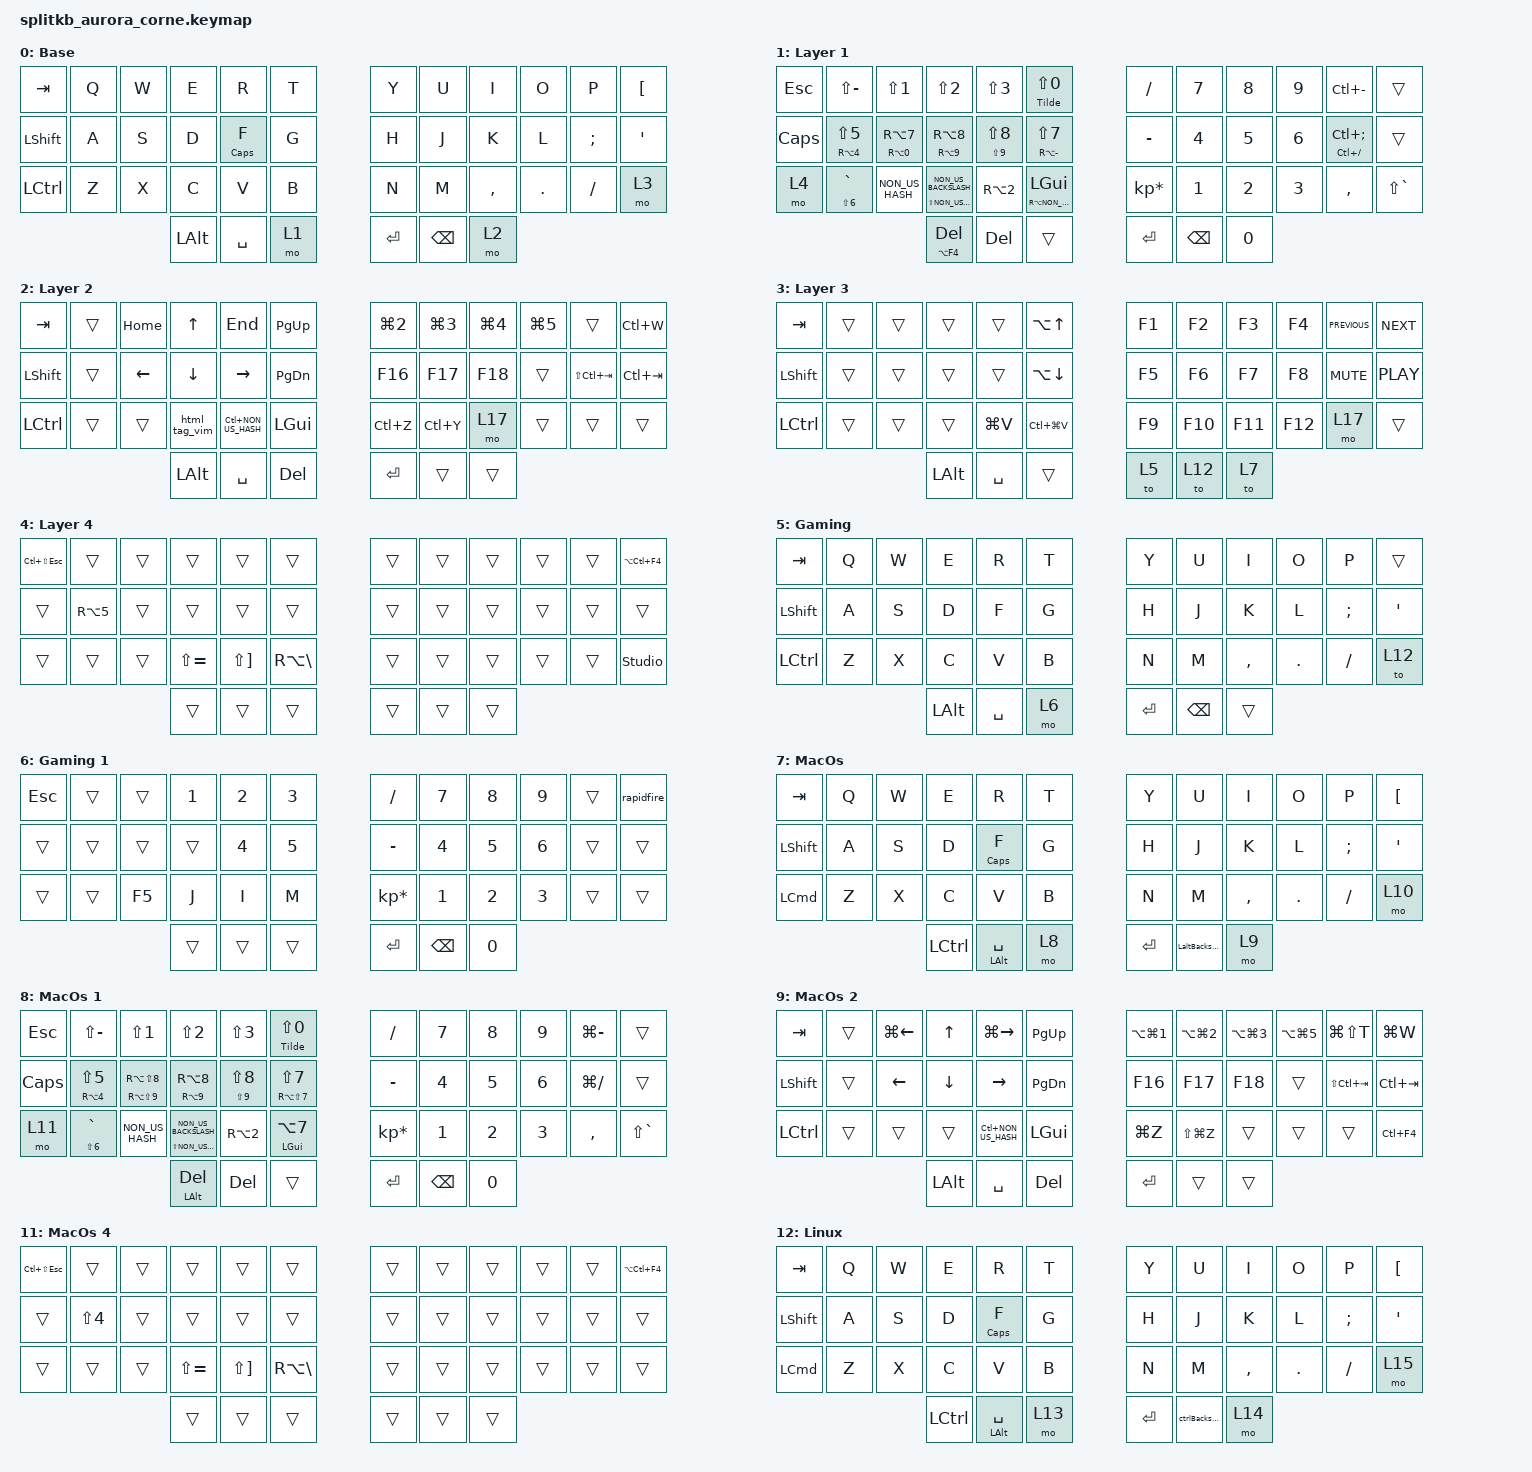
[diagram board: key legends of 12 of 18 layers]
/*
 * Copyright (c) 2020 The ZMK Contributors
 *
 * SPDX-License-Identifier: MIT
 */

#include <behaviors.dtsi>
#include <dt-bindings/zmk/bt.h>
#include <dt-bindings/zmk/keys.h>

/ {
    macros {
        Tilde: Tilde {
            compatible = "zmk,behavior-macro";
            #binding-cells = <0>;
            bindings = <&kp RA(RIGHT_BRACKET) &kp SPACE>;
            label = "TILDE";
        };

        html_tag_vim: html_tag_vim {
            compatible = "zmk,behavior-macro";
            #binding-cells = <0>;
            bindings = <&kp Y &kp S &kp L &kp NON_US_BACKSLASH>;
            label = "HTML_TAG_VIM";
        };

        rampytys: rampytys {
            compatible = "zmk,behavior-macro";
            #binding-cells = <0>;
            bindings = <&kp SPACE &kp SPACE &kp SPACE &kp SPACE &kp SPACE &kp SPACE &kp SPACE &kp SPACE &kp SPACE &kp SPACE &kp SPACE &kp SPACE &kp SPACE &kp SPACE &kp SPACE &kp SPACE &kp SPACE &kp SPACE &kp SPACE &kp SPACE &kp SPACE &kp SPACE &kp SPACE &kp SPACE &kp SPACE &kp SPACE &kp SPACE &kp SPACE &kp SPACE &kp SPACE &kp SPACE &kp SPACE &kp SPACE &kp SPACE &kp SPACE &kp SPACE &kp SPACE &kp SPACE &kp SPACE &kp SPACE &kp SPACE &kp SPACE &kp SPACE &kp SPACE &kp SPACE &kp SPACE &kp SPACE &kp SPACE &kp SPACE &kp SPACE &kp SPACE &kp SPACE &kp SPACE &kp SPACE &kp SPACE &kp SPACE &kp SPACE &kp SPACE &kp SPACE &kp SPACE &kp SPACE &kp SPACE &kp SPACE &kp SPACE &kp SPACE &kp SPACE &kp SPACE &kp SPACE &kp SPACE &kp SPACE &kp SPACE &kp SPACE &kp SPACE &kp SPACE &kp SPACE &kp SPACE &kp SPACE &kp SPACE &kp SPACE &kp SPACE &kp SPACE &kp SPACE &kp SPACE &kp SPACE &kp SPACE &kp SPACE &kp SPACE &kp SPACE &kp SPACE &kp SPACE &kp SPACE &kp SPACE &kp SPACE &kp SPACE &kp SPACE &kp SPACE &kp SPACE &kp SPACE &kp SPACE &kp SPACE &kp SPACE &kp SPACE &kp SPACE &kp SPACE &kp SPACE &kp SPACE &kp SPACE &kp SPACE &kp SPACE &kp SPACE &kp SPACE &kp SPACE &kp SPACE &kp SPACE &kp SPACE &kp SPACE &kp SPACE &kp SPACE &kp SPACE &kp SPACE &kp SPACE &kp SPACE &kp SPACE &kp SPACE &kp SPACE &kp SPACE &kp SPACE &kp SPACE &kp SPACE &kp SPACE &kp SPACE &kp SPACE &kp SPACE &kp SPACE &kp SPACE &kp SPACE &kp SPACE &kp SPACE &kp SPACE &kp SPACE &kp SPACE &kp SPACE &kp SPACE &kp SPACE &kp SPACE &kp SPACE &kp SPACE &kp SPACE &kp SPACE &kp SPACE &kp SPACE &kp SPACE &kp SPACE &kp SPACE &kp SPACE &kp SPACE &kp SPACE &kp SPACE &kp SPACE &kp SPACE &kp SPACE &kp SPACE>;
            label = "RAMPYTYS";
            wait-ms = <150>;
        };
    };

    behaviors {
        rapidfire: rapidfire {
            compatible = "zmk,behavior-rapidfire";
            #binding-cells = <0>;
            label = "RAPIDFIRE";
            keycode = <E>;
            tap-ms = <6>;
            wait-ms = <3>;
        };

        equals_tilde: equals_tilde {
            compatible = "zmk,behavior-hold-tap";
            label = "EQUALS_TILDE";
            bindings = <&Tilde>, <&kp>;

            #binding-cells = <2>;
            tapping-term-ms = <150>;
        };

        Custom_Hold_Tap: Custom_Hold_Tap {
            compatible = "zmk,behavior-hold-tap";
            label = "CUSTOM_HOLD_TAP";
            bindings = <&kp>, <&kp>;

            #binding-cells = <2>;
            tapping-term-ms = <200>;
            flavor = "tap-preferred";
        };

        LaltBackspace: LaltBackspace {
            compatible = "zmk,behavior-mod-morph";
            label = "LALTBACKSPACE";
            bindings = <&kp BACKSPACE>, <&kp LA(BACKSPACE)>;

            #binding-cells = <0>;
            mods = <(MOD_LGUI)>;
        };

        ctrlBackspace: ctrlBackspace {
            compatible = "zmk,behavior-mod-morph";
            label = "CTRLBACKSPACE";
            bindings = <&kp BACKSPACE>, <&kp LC(BACKSPACE)>;

            #binding-cells = <0>;
            mods = <(MOD_LGUI)>;
        };
    };

    combos { compatible = "zmk,combos"; };

    keymap {
        compatible = "zmk,keymap";

        default_layer {
            display-name = "Base";

            // -----------------------------------------------------------------------------------------
            // |  TAB |  Q  |  W  |  E  |  R  |  T  |   |  Y  |  U   |  I  |  O  |  P  | BKSP |
            // | CTRL |  A  |  S  |  D  |  F  |  G  |   |  H  |  J   |  K  |  L  |  ;  |  '   |
            // | SHFT |  Z  |  X  |  C  |  V  |  B  |   |  N  |  M   |  ,  |  .  |  /  | ESC  |
            //                    | GUI | LWR | SPC |   | ENT | RSE  | ALT |

            bindings = <
&kp TAB         &kp Q  &kp W  &kp E         &kp R                    &kp T    &kp Y    &kp U          &kp I      &kp O    &kp P     &kp LEFT_BRACKET
&kp LEFT_SHIFT  &kp A  &kp S  &kp D         &Custom_Hold_Tap CAPS F  &kp G    &kp H    &kp J          &kp K      &kp L    &kp SEMI  &kp SINGLE_QUOTE
&kp LCTRL       &kp Z  &kp X  &kp C         &kp V                    &kp B    &kp N    &kp M          &kp COMMA  &kp DOT  &kp FSLH  &mo 3
                              &kp LEFT_ALT  &kp SPACE                &mo 1    &kp RET  &kp BACKSPACE  &mo 2
            >;
        };

        lower_layer {
            display-name = "Layer 1";

            // -----------------------------------------------------------------------------------------
            // |  TAB |  1  |  2  |  3  |  4  |  5  |   |  6  |  7  |  8  |  9  |  0  | BKSP |
            // | BTCLR| BT1 | BT2 | BT3 | BT4 | BT5 |   | LFT | DWN |  UP | RGT |     |      |
            // | SHFT |     |     |     |     |     |   |     |     |     |     |     |      |
            //                    | GUI |     | SPC |   | ENT |     | ALT |

            bindings = <
&kp ESCAPE  &kp LS(MINUS)                  &kp LS(NUMBER_1)               &kp LS(NUMBER_2)                           &kp LS(NUMBER_3)               &equals_tilde 0 LS(NUMBER_0)     &kp SLASH        &kp NUMBER_7   &kp N8        &kp N9        &kp LC(MINUS)                &trans
&kp CAPS    &mt RA(NUMBER_4) LS(NUMBER_5)  &mt RA(NUMBER_0) RA(NUMBER_7)  &mt RA(NUMBER_9) RA(NUMBER_8)              &mt LS(NUMBER_9) LS(NUMBER_8)  &mt RA(MINUS) LS(NUMBER_7)       &kp MINUS        &kp NUMBER_4   &kp NUMBER_5  &kp NUMBER_6  &mt LC(SLASH) LC(SEMICOLON)  &trans
&mo 4       &mt LS(NUMBER_6) GRAVE         &kp NON_US_HASH                &mt LS(NON_US_BACKSLASH) NON_US_BACKSLASH  &kp RA(NUMBER_2)               &mt RA(NON_US_BACKSLASH) LGUI    &kp KP_ASTERISK  &kp NUMBER_1   &kp NUMBER_2  &kp NUMBER_3  &kp COMMA                    &kp LS(GRAVE)
                                                                          &mt LA(F4) DELETE                          &kp DELETE                     &trans                           &kp RET          &kp BACKSPACE  &kp NUMBER_0
            >;
        };

        raise_layer {
            display-name = "Layer 2";

            // -----------------------------------------------------------------------------------------
            // |  TAB |  !  |  @  |  #  |  $  |  %  |   |  ^  |  &  |  *  |  (  |  )  | BKSP |
            // | CTRL |     |     |     |     |     |   |  -  |  =  |  [  |  ]  |  \  |  `   |
            // | SHFT |     |     |     |     |     |   |  _  |  +  |  {  |  }  | "|" |  ~   |
            //                    | GUI |     | SPC |   | ENT |     | ALT |

            bindings = <
&kp TAB         &trans  &kp HOME  &kp UP         &kp END              &kp PAGE_UP      &kp LG(NUMBER_2)  &kp LG(NUMBER_3)  &kp LG(NUMBER_4)  &kp LG(NUMBER_5)  &trans           &kp LC(W)
&kp LEFT_SHIFT  &trans  &kp LEFT  &kp DOWN       &kp RIGHT            &kp PAGE_DOWN    &kp F16           &kp F17           &kp F18           &trans            &kp LS(LC(TAB))  &kp LC(TAB)
&kp LCTRL       &trans  &trans    &html_tag_vim  &kp LC(NON_US_HASH)  &kp LGUI         &kp LC(Z)         &kp LC(Y)         &mo 17            &trans            &trans           &trans
                                  &kp LEFT_ALT   &kp SPACE            &kp DEL          &kp RET           &trans            &trans
            >;
        };

        layer_3 {
            display-name = "Layer 3";
            bindings = <
&kp TAB         &trans  &trans  &trans        &trans     &kp LA(UP_ARROW)    &kp F1  &kp F2   &kp F3   &kp F4   &kp C_PREVIOUS  &kp C_NEXT
&kp LEFT_SHIFT  &trans  &trans  &trans        &trans     &kp LA(DOWN)        &kp F5  &kp F6   &kp F7   &kp F8   &kp C_MUTE      &kp C_PLAY
&kp LCTRL       &trans  &trans  &trans        &kp LG(V)  &kp LC(LG(V))       &kp F9  &kp F10  &kp F11  &kp F12  &mo 17          &trans
                                &kp LEFT_ALT  &kp SPACE  &trans              &to 5   &to 12   &to 7
            >;
        };

        layer_4 {
            display-name = "Layer 4";
            bindings = <
&kp LC(LS(ESCAPE))  &trans            &trans  &trans         &trans                 &trans               &trans  &trans  &trans  &trans  &trans  &kp LA(LC(F4))
&trans              &kp RA(NUMBER_5)  &trans  &trans         &trans                 &trans               &trans  &trans  &trans  &trans  &trans  &trans
&trans              &trans            &trans  &kp LS(EQUAL)  &kp LS(RIGHT_BRACKET)  &kp RA(BACKSLASH)    &trans  &trans  &trans  &trans  &trans  &studio_unlock
                                              &trans         &trans                 &trans               &trans  &trans  &trans
            >;
        };

        Gaming {
            display-name = "Gaming";
            bindings = <
&kp TAB           &kp Q  &kp W  &kp E         &kp R      &kp T    &kp Y      &kp U          &kp I      &kp O       &kp P          &trans
&kp LEFT_SHIFT    &kp A  &kp S  &kp D         &kp F      &kp G    &kp H      &kp J          &kp K      &kp L       &kp SEMICOLON  &kp SINGLE_QUOTE
&kp LEFT_CONTROL  &kp Z  &kp X  &kp C         &kp V      &kp B    &kp N      &kp M          &kp COMMA  &kp PERIOD  &kp SLASH      &to 12
                                &kp LEFT_ALT  &kp SPACE  &mo 6    &kp ENTER  &kp BACKSPACE  &trans
            >;
        };

        Gaming_1 {
            display-name = "Gaming 1";
            bindings = <
&kp ESCAPE  &trans  &trans  &kp NUMBER_1  &kp NUMBER_2  &kp NUMBER_3    &kp SLASH        &kp N7         &kp N8        &kp N9        &trans  &rapidfire
&trans      &trans  &trans  &trans        &kp NUMBER_4  &kp NUMBER_5    &kp MINUS        &kp NUMBER_4   &kp N5        &kp NUMBER_6  &trans  &trans
&trans      &trans  &kp F5  &kp J         &kp I         &kp M           &kp KP_MULTIPLY  &kp NUMBER_1   &kp NUMBER_2  &kp NUMBER_3  &trans  &trans
                            &trans        &trans        &trans          &kp ENTER        &kp BACKSPACE  &kp N0
            >;
        };

        MacOs {
            display-name = "MacOs";
            bindings = <
&kp TAB           &kp Q  &kp W  &kp E             &kp R                            &kp T    &kp Y    &kp U           &kp I      &kp O    &kp P     &kp LEFT_BRACKET
&kp LEFT_SHIFT    &kp A  &kp S  &kp D             &Custom_Hold_Tap CAPS F          &kp G    &kp H    &kp J           &kp K      &kp L    &kp SEMI  &kp SINGLE_QUOTE
&kp LEFT_COMMAND  &kp Z  &kp X  &kp C             &kp V                            &kp B    &kp N    &kp M           &kp COMMA  &kp DOT  &kp FSLH  &mo 10
                                &kp LEFT_CONTROL  &Custom_Hold_Tap LEFT_ALT SPACE  &mo 8    &kp RET  &LaltBackspace  &mo 9
            >;
        };

        MacOs_1 {
            display-name = "MacOs 1";
            bindings = <
&kp ESCAPE  &kp LS(MINUS)                  &kp LS(NUMBER_1)           &kp LS(NUMBER_2)                           &kp LS(NUMBER_3)               &equals_tilde 0 LS(NUMBER_0)    &kp SLASH        &kp NUMBER_7   &kp N8        &kp N9        &kp LG(MINUS)  &trans
&kp CAPS    &mt RA(NUMBER_4) LS(NUMBER_5)  &mt RA(LS(N9)) RA(LS(N8))  &mt RA(NUMBER_9) RA(NUMBER_8)              &mt LS(NUMBER_9) LS(NUMBER_8)  &mt RA(LS(N7)) LS(NUMBER_7)     &kp MINUS        &kp NUMBER_4   &kp NUMBER_5  &kp NUMBER_6  &kp LG(SLASH)  &trans
&mo 11      &mt LS(NUMBER_6) GRAVE         &kp NON_US_HASH            &mt LS(NON_US_BACKSLASH) NON_US_BACKSLASH  &kp RA(NUMBER_2)               &mt LGUI LA(N7)                 &kp KP_ASTERISK  &kp NUMBER_1   &kp NUMBER_2  &kp NUMBER_3  &kp COMMA      &kp LS(GRAVE)
                                                                      &mt LEFT_ALT DELETE                        &kp DELETE                     &trans                          &kp RET          &kp BACKSPACE  &kp NUMBER_0
            >;
        };

        MacOs_2 {
            display-name = "MacOs 2";
            bindings = <
&kp TAB         &trans  &kp LG(LEFT)  &kp UP        &kp LG(RIGHT_ARROW)  &kp PAGE_UP      &kp LA(LG(NUMBER_1))  &kp LA(LG(NUMBER_2))  &kp LA(LG(NUMBER_3))  &kp LA(LG(N5))  &kp LG(LS(T))    &kp LG(W)
&kp LEFT_SHIFT  &trans  &kp LEFT      &kp DOWN      &kp RIGHT            &kp PAGE_DOWN    &kp F16               &kp F17               &kp F18               &trans          &kp LS(LC(TAB))  &kp LC(TAB)
&kp LCTRL       &trans  &trans        &trans        &kp LC(NON_US_HASH)  &kp LGUI         &kp LG(Z)             &kp LS(LG(Z))         &trans                &trans          &trans           &kp LC(F4)
                                      &kp LEFT_ALT  &kp SPACE            &kp DEL          &kp RET               &trans                &trans
            >;
        };

        MacOs_3 {
            display-name = "MacOs 3";
            bindings = <
&kp TAB         &trans  &trans              &kp LC(UP_ARROW)  &trans                    &kp LA(UP_ARROW)      &kp F1  &kp F2   &kp F3   &kp F4   &kp C_PREVIOUS  &kp C_NEXT
&kp LEFT_SHIFT  &trans  &kp LC(LEFT_ARROW)  &kp LC(DOWN)      &kp LC(RIGHT_ARROW)       &kp LA(DOWN_ARROW)    &kp F5  &kp F6   &kp F7   &kp F8   &kp C_MUTE      &kp C_PLAY
&kp LCTRL       &trans  &trans              &kp LS(LG(N5))    &kp LS(LG(LC(NUMBER_4)))  &kp LG(LS(LA(V)))     &kp F9  &kp F10  &kp F11  &kp F12  &mo 17          &trans
                                            &kp LEFT_ALT      &kp SPACE                 &trans                &to 5   &to 12   &to 0
            >;
        };

        MacOs_4 {
            display-name = "MacOs 4";
            bindings = <
&kp LC(LS(ESCAPE))  &trans            &trans  &trans         &trans                 &trans               &trans  &trans  &trans  &trans  &trans  &kp LA(LC(F4))
&trans              &kp LS(NUMBER_4)  &trans  &trans         &trans                 &trans               &trans  &trans  &trans  &trans  &trans  &trans
&trans              &trans            &trans  &kp LS(EQUAL)  &kp LS(RIGHT_BRACKET)  &kp RA(BACKSLASH)    &trans  &trans  &trans  &trans  &trans  &trans
                                              &trans         &trans                 &trans               &trans  &trans  &trans
            >;
        };

        Linux {
            display-name = "Linux";
            bindings = <
&kp TAB           &kp Q  &kp W  &kp E             &kp R                            &kp T     &kp Y    &kp U           &kp I      &kp O    &kp P     &kp LEFT_BRACKET
&kp LEFT_SHIFT    &kp A  &kp S  &kp D             &Custom_Hold_Tap CAPS F          &kp G     &kp H    &kp J           &kp K      &kp L    &kp SEMI  &kp SINGLE_QUOTE
&kp LEFT_COMMAND  &kp Z  &kp X  &kp C             &kp V                            &kp B     &kp N    &kp M           &kp COMMA  &kp DOT  &kp FSLH  &mo 15
                                &kp LEFT_CONTROL  &Custom_Hold_Tap LEFT_ALT SPACE  &mo 13    &kp RET  &ctrlBackspace  &mo 14
            >;
        };

        Linux_1 {
            display-name = "Linux 1";
            bindings = <
&kp ESCAPE  &kp LS(MINUS)                  &kp LS(NUMBER_1)               &kp LS(NUMBER_2)                           &kp LS(NUMBER_3)               &equals_tilde 0 LS(NUMBER_0)     &kp SLASH        &kp NUMBER_7   &kp N8        &kp N9        &kp LC(MINUS)  &trans
&kp CAPS    &mt RA(NUMBER_4) LS(NUMBER_5)  &mt RA(NUMBER_0) RA(NUMBER_7)  &mt RA(NUMBER_9) RA(NUMBER_8)              &mt LS(NUMBER_9) LS(NUMBER_8)  &mt RA(MINUS) LS(NUMBER_7)       &kp MINUS        &kp NUMBER_4   &kp NUMBER_5  &kp NUMBER_6  &kp LC(SLASH)  &trans
&mo 16      &mt LS(NUMBER_6) GRAVE         &kp NON_US_HASH                &mt LS(NON_US_BACKSLASH) NON_US_BACKSLASH  &kp RA(NUMBER_2)               &mt LG(LA(V)) RA(NON_US_BSLH)    &kp KP_ASTERISK  &kp NUMBER_1   &kp NUMBER_2  &kp NUMBER_3  &kp COMMA      &kp LS(GRAVE)
                                                                          &mt LEFT_ALT DELETE                        &kp DELETE                     &trans                           &kp RET          &kp BACKSPACE  &kp NUMBER_0
            >;
        };

        Linux_2 {
            display-name = "Linux 2";
            bindings = <
&kp TAB         &trans  &kp HOME  &kp UP        &kp END              &kp PAGE_UP      &kp LA(NUMBER_1)  &kp LA(NUMBER_2)  &kp LA(NUMBER_3)  &kp LA(N5)  &kp LG(LS(T))    &kp LC(W)
&kp LEFT_SHIFT  &trans  &kp LEFT  &kp DOWN      &kp RIGHT            &kp PAGE_DOWN    &kp F16           &kp F17           &kp F18           &kp F19     &kp LS(LC(TAB))  &kp LC(TAB)
&kp LCTRL       &trans  &trans    &trans        &kp LC(NON_US_HASH)  &kp LGUI         &kp LC(Z)         &kp LS(LC(Z))     &trans            &trans      &trans           &kp LC(F4)
                                  &kp LEFT_ALT  &kp SPACE            &kp DEL          &kp RET           &trans            &trans
            >;
        };

        Linux_3 {
            display-name = "Linux 3";
            bindings = <
&kp TAB         &trans  &trans              &kp LC(UP_ARROW)  &trans                    &kp LA(UP_ARROW)      &kp F1  &kp F2   &kp F3   &kp F4   &kp C_PREVIOUS  &kp C_NEXT
&kp LEFT_SHIFT  &trans  &kp LC(LEFT_ARROW)  &kp LC(DOWN)      &kp LC(RIGHT_ARROW)       &kp LA(DOWN_ARROW)    &kp F5  &kp F6   &kp F7   &kp F8   &kp C_MUTE      &kp C_PLAY
&kp LCTRL       &trans  &trans              &kp LS(LG(N5))    &kp LS(LG(LC(NUMBER_4)))  &kp LG(LS(LA(V)))     &kp F9  &kp F10  &kp F11  &kp F12  &mo 17          &trans
                                            &kp LEFT_ALT      &kp SPACE                 &trans                &to 5   &to 0    &to 7
            >;
        };

        Linux_4 {
            display-name = "Linux 4";
            bindings = <
&kp LC(LS(ESCAPE))  &trans            &trans  &trans         &trans                 &trans               &trans  &trans            &trans            &trans            &trans  &kp LA(LC(F4))
&kp LEFT_SHIFT      &kp RA(NUMBER_5)  &trans  &trans         &trans                 &trans               &trans  &kp LG(NUMBER_4)  &kp LG(NUMBER_5)  &trans            &trans  &trans
&trans              &trans            &trans  &kp LS(EQUAL)  &kp LS(RIGHT_BRACKET)  &kp RA(BACKSLASH)    &trans  &kp LG(NUMBER_1)  &kp LG(NUMBER_2)  &kp LG(NUMBER_3)  &trans  &trans
                                              &trans         &trans                 &trans               &trans  &trans            &trans
            >;
        };

        Settings {
            display-name = "Settings";
            bindings = <
&trans  &trans  &trans  &trans      &trans      &trans        &trans  &trans  &trans  &trans       &trans  &trans
&trans  &trans  &trans  &trans      &trans      &trans        &trans  &trans  &trans  &trans       &trans  &trans
&trans  &trans  &trans  &trans      &trans      &trans        &trans  &trans  &trans  &kp K_POWER  &trans  &trans
                        &bt BT_CLR  &bt BT_PRV  &bt BT_NXT    &trans  &trans  &trans
            >;
        };
    };

    conditional_layers { compatible = "zmk,conditional-layers"; };
};
